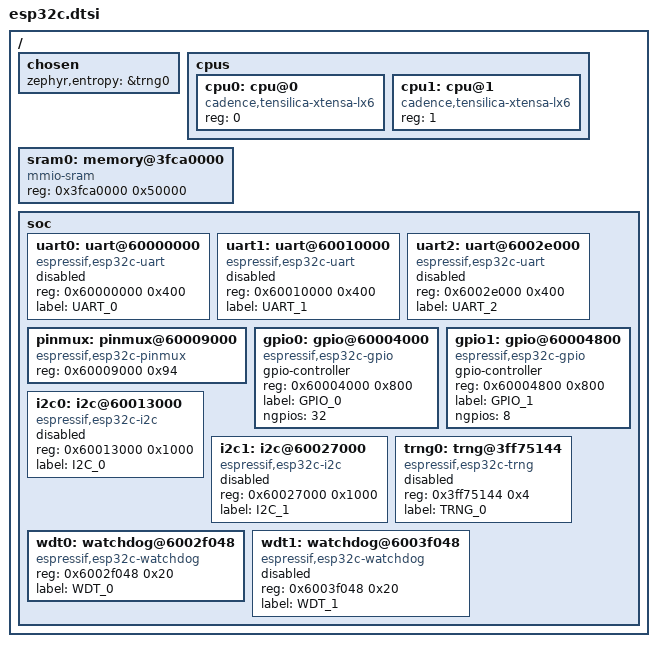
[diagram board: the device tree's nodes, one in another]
/*
 * Copyright (c) 2020 Espressif Corporation.
 *
 * SPDX-License-Identifier: Apache-2.0
 */
#include <xtensa/xtensa.dtsi>
#include <dt-bindings/gpio/gpio.h>
#include <dt-bindings/i2c/i2c.h>

/ {
	chosen {
		zephyr,entropy = &trng0;
	};

	cpus {
		#address-cells = <1>;
		#size-cells = <0>;

		cpu0: cpu@0 {
			device_type = "cpu";
			compatible = "cadence,tensilica-xtensa-lx6";
			reg = <0>;
		};

		cpu1: cpu@1 {
			device_type = "cpu";
			compatible = "cadence,tensilica-xtensa-lx6";
			reg = <1>;
		};

	};

	sram0: memory@3fca0000 {
		device_type = "memory";
		compatible = "mmio-sram";
		reg = <0x3fca0000 0x50000>;
	};

	soc {
		uart0: uart@60000000 {
			compatible = "espressif,esp32c-uart";
			reg = <0x60000000 0x400>;
			/* interrupts = <12>; - FIXME: Enable interrupts when interrupt-controller got supported in device tree */
			label = "UART_0";
			status = "disabled";
		};

		uart1: uart@60010000 {
			compatible = "espressif,esp32c-uart";
			reg = <0x60010000 0x400>;
			/* interrupts = <17>; - FIXME: Enable interrupts when interrupt-controller got supported in device tree */
			label = "UART_1";
			status = "disabled";
		};

		uart2: uart@6002e000 {
			compatible = "espressif,esp32c-uart";
			reg = <0x6002e000 0x400>;
			/* interrupts = <18>; - FIXME: Enable interrupts when interrupt-controller got supported in device tree */
			label = "UART_2";
			status = "disabled";
		};

		pinmux: pinmux@60009000 {
			compatible = "espressif,esp32c-pinmux";
			reg = <0x60009000 0x94>;
		};

		gpio0: gpio@60004000 {
			compatible = "espressif,esp32c-gpio";
			gpio-controller;
			#gpio-cells = <2>;
			reg = <0x60004000 0x800>;
			label = "GPIO_0";
			ngpios = <32>;   /* 0..31 */
		};

		gpio1: gpio@60004800 {
			compatible = "espressif,esp32c-gpio";
			gpio-controller;
			#gpio-cells = <2>;
			reg = <0x60004800 0x800>;
			label = "GPIO_1";
			ngpios = <8>;   /* 32..39 */
		};

		i2c0: i2c@60013000 {
			compatible = "espressif,esp32c-i2c";
			#address-cells = <1>;
			#size-cells = <0>;
			reg = <0x60013000 0x1000>;
			/* interrupts = <8>; - FIXME: Enable interrupts when interrupt-controller got supported in device tree */
			label = "I2C_0";
			status = "disabled";
		};

		i2c1: i2c@60027000 {
			compatible = "espressif,esp32c-i2c";
			#address-cells = <1>;
			#size-cells = <0>;
			reg = <0x60027000 0x1000>;
			/* interrupts = <9>; - FIXME: Enable interrupts when interrupt-controller got supported in device tree */
			label = "I2C_1";
			status = "disabled";
		};

		trng0: trng@3ff75144 {
			compatible = "espressif,esp32c-trng";
			reg = <0x3ff75144 0x4>;
			/* interrupts = <33 0>; - FIXME: Enable interrupts when interrupt-controller got supported in device tree */
			label = "TRNG_0";
			status = "disabled";
		};

		wdt0: watchdog@6002f048 {
			compatible = "espressif,esp32c-watchdog";
			reg = <0x6002f048 0x20>;
			/* interrupts = <24>; - FIXME: Enable interrupts when interrupt-controller got supported in device tree */
			label = "WDT_0";
			status = "okay";
		};

		wdt1: watchdog@6003f048 {
			compatible = "espressif,esp32c-watchdog";
			reg = <0x6003f048 0x20>;
			/* interrupts = <25>; - FIXME: Enable interrupts when interrupt-controller got supported in device tree */
			label = "WDT_1";
			status = "disabled";
		};
	};
};
